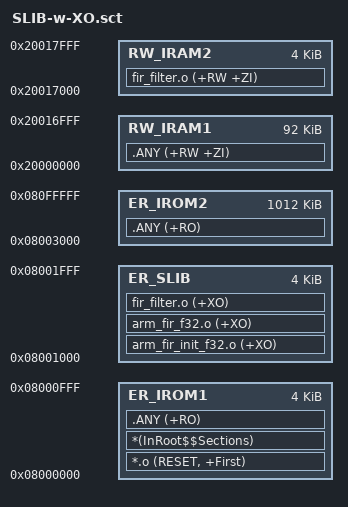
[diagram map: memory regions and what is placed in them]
; *************************************************************
; *** Scatter-Loading Description File generated by uVision ***
; *************************************************************

; This Scatter file is used for AT32F403AVGT7 ( flash size is 1024KB, page size is 2KB)

LR_IROM1 0x08000000 0x00001000  {    ; user code area
  ER_IROM1 0x08000000 0x00001000  {  ; load address = execution address
   *.o (RESET, +First)
   *(InRoot$$Sections)
   .ANY (+RO)
  }
  RW_IRAM1 0x20000000 0x00017000  {  ; user RAM area
   .ANY (+RW +ZI)
  }
  
  RW_IRAM2 0x20017000 0x00001000  {  ; RAM used for sLIB code
   fir_filter.o (+RW +ZI) 
  }  
  
}

LR_SLIB 0x08001000 0x00001000  {    ; sLib code
  ER_SLIB 0x08001000 0x00001000  {  ; load address = execution address
    
	arm_fir_init_f32.o (+XO)
	arm_fir_f32.o (+XO)
	fir_filter.o (+XO)
  }
}

; User can also use this section to place sLib data
;LR_SLIB_DATA 0x08002000 0x00001000  {    ; sLib data
;  ER_SLIB_DATA 0x08002000 0x00001000  {  
;   fir_coefficient.o (+RO)   
;  }
;}

LR_IROM2 0x08003000 0x000FD000  {    ; user code area
  ER_IROM2 0x08003000 0x000FD000  {  ; load address = execution address
   .ANY (+RO)
  }
}

